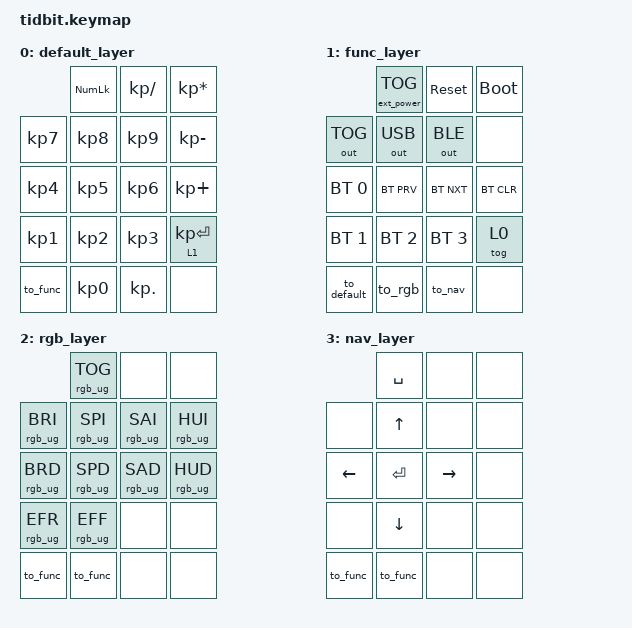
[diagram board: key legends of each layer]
/*
 * Copyright (c) 2020 The ZMK Contributors
 *
 * SPDX-License-Identifier: MIT
 */

#include <behaviors.dtsi>
#include <dt-bindings/zmk/bt.h>
#include <dt-bindings/zmk/outputs.h>
#include <dt-bindings/zmk/keys.h>

#include <dt-bindings/zmk/ext_power.h>

#define DEFAULT 0
#define FUNC    1
#define RGB    2
#define NAV    3
#define NONE 0

&encoder_1_top_row {
	status = "okay";
};

/ {
    macros {
        to_func: to_func {
            label = "ZM_to_func";
            compatible = "zmk,behavior-macro";
            #binding-cells = <0>;
            wait-ms = <0>;
            tap-ms = <0>;
            bindings
                = <&macro_tap &to FUNC>
                //, <&macro_tap &rgb_ug RGB_COLOR_HSB(120,100,100)>
                ;
        };
        to_rgb: to_rgb {
            label = "ZM_to_rgb";
            compatible = "zmk,behavior-macro";
            #binding-cells = <0>;
            wait-ms = <0>;
            tap-ms = <0>;
            bindings
                = <&macro_tap &to RGB>
                //, <&macro_tap &rgb_ug RGB_COLOR_HSB(0,100,100)>
                ;
        };
        to_default: to_default {
            label = "ZM_to_default";
            compatible = "zmk,behavior-macro";
            #binding-cells = <0>;
            wait-ms = <0>;
            tap-ms = <0>;
            bindings
                = <&macro_tap &to DEFAULT>
                //, <&macro_tap &rgb_ug RGB_COLOR_HSB(240,100,100)>
                ;
        };
        to_nav: to_nav {
            label = "ZM_to_nav";
            compatible = "zmk,behavior-macro";
            #binding-cells = <0>;
            wait-ms = <0>;
            tap-ms = <0>;
            bindings
                = <&macro_tap &to NAV>
                //, <&macro_tap &rgb_ug RGB_COLOR_HSB(240,0,100)>
                ;
        };
    };
	sensors {
		compatible = "zmk,keymap-sensors";
		sensors = <&encoder_1_top_row>;
	};

	keymap {
		compatible = "zmk,keymap";
		
		default_layer {
			bindings = <
								&kp KP_NUMLOCK  &kp KP_DIVIDE   &kp KP_ASTERISK
				&kp KP_NUMBER_7 &kp KP_NUMBER_8 &kp KP_NUMBER_9 &kp KP_MINUS
				&kp KP_NUMBER_4 &kp KP_NUMBER_5 &kp KP_NUMBER_6 &kp KP_PLUS
				&kp KP_NUMBER_1 &kp KP_NUMBER_2 &kp KP_NUMBER_3 &lt 1 KP_ENTER
				&to_func        &kp KP_NUMBER_0 &kp KP_DOT      &none
			>;

			sensor-bindings = <&inc_dec_kp C_VOLUME_UP C_VOLUME_DOWN>;
		};

		func_layer {
			 bindings = <
								&ext_power EP_TOG&sys_reset         &bootloader
				&out OUT_TOG    &out OUT_USB    &out OUT_BLE    &none
				&bt BT_SEL 0    &bt BT_PRV      &bt BT_NXT      &bt BT_CLR
				&bt BT_SEL 1    &bt BT_SEL 2    &bt BT_SEL 3    &tog 0
				&to_default     &to_rgb         &to_nav         &none
			 >;

			 sensor-bindings = <&inc_dec_kp DOWN UP>;
		 };

		rgb_layer {
			 bindings = <
								&rgb_ug RGB_TOG &none           &none
				&rgb_ug RGB_BRI &rgb_ug RGB_SPI &rgb_ug RGB_SAI &rgb_ug RGB_HUI
				&rgb_ug RGB_BRD &rgb_ug RGB_SPD &rgb_ug RGB_SAD &rgb_ug RGB_HUD
				&rgb_ug RGB_EFR &rgb_ug RGB_EFF &none           &none 
				&to_func        &to_func        &none           &none 
			 >;

			 sensor-bindings = <&inc_dec_kp DOWN UP>;
		 };

		nav_layer {
			 bindings = <
								&kp SPACE       &none           &none
				&none           &kp UP          &none           &none
				&kp LEFT        &kp ENTER       &kp RIGHT       &none
				&none           &kp DOWN        &none           &none 
				&to_func        &to_func        &none           &none 
			 >;

			 sensor-bindings = <&inc_dec_kp RIGHT LEFT>;
		 };
	};
};
